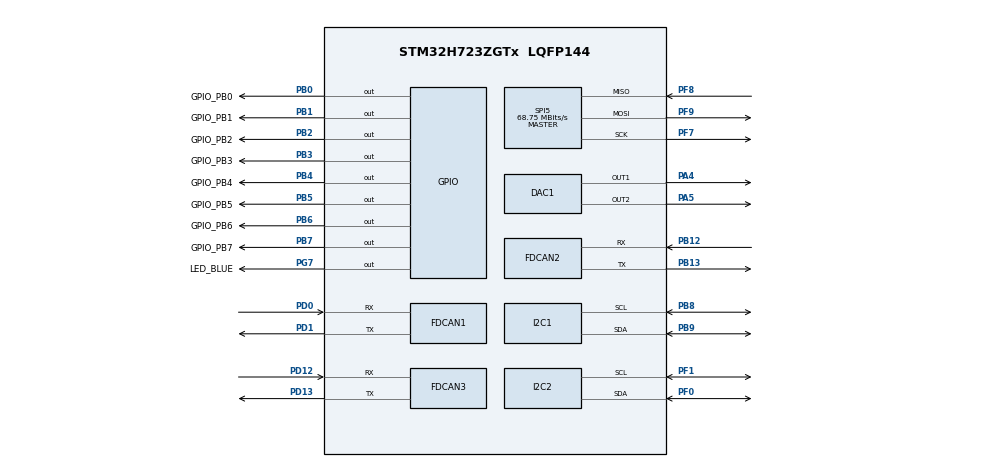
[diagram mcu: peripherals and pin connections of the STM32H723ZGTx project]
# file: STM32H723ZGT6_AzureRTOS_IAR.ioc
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CORTEX_M7.default_mode_Activation=1
DAC1.DAC_Channel-DAC_OUT1=DAC_CHANNEL_1
DAC1.DAC_Channel-DAC_OUT2=DAC_CHANNEL_2
FDCAN1.CalculateBaudRateNominal=500000
FDCAN1.CalculateTimeBitNominal=2000
FDCAN1.CalculateTimeQuantumNominal=125.0
FDCAN1.NominalPrescaler=10
FDCAN1.NominalTimeSeg1=13
FDCAN1.NominalTimeSeg2=2
FDCAN1.TxBuffersNbr=32
FDCAN2.CalculateBaudRateNominal=500000
FDCAN2.CalculateTimeBitNominal=2000
FDCAN2.CalculateTimeQuantumNominal=125.0
FDCAN2.NominalPrescaler=10
FDCAN2.NominalTimeSeg1=13
FDCAN2.NominalTimeSeg2=2
FDCAN2.TxBuffersNbr=32
FDCAN3.CalculateBaudRateNominal=500000
FDCAN3.CalculateTimeBitNominal=2000
FDCAN3.CalculateTimeQuantumNominal=125.0
FDCAN3.NominalPrescaler=10
FDCAN3.NominalTimeSeg1=13
FDCAN3.NominalTimeSeg2=2
FDCAN3.TxBuffersNbr=32
I2C1.Timing=0x60404E72
I2C2.Timing=0x60404E72
Mcu.Family=STM32H7
Mcu.Name=STM32H723ZGTx
Mcu.Package=LQFP144
NVIC.PriorityGroup=NVIC_PRIORITYGROUP_4
NVIC.TIM23_IRQn=true\:15\:0\:false\:false\:true\:false\:false\:true\:true
NVIC.TimeBase=TIM23_IRQn
NVIC.TimeBaseIP=TIM23
PA4.Signal=COMP_DAC11_group
PA5.Signal=COMP_DAC12_group
PB0.GPIO_Label=GPIO_PB0
PB0.Signal=GPIO_Output
PB1.GPIO_Label=GPIO_PB1
PB1.Signal=GPIO_Output
PB12.Mode=FDCAN_Activate
PB12.Signal=FDCAN2_RX
PB13.Mode=FDCAN_Activate
PB13.Signal=FDCAN2_TX
PB2.GPIO_Label=GPIO_PB2
PB2.Signal=GPIO_Output
PB3(JTDO/TRACESWO).GPIO_Label=GPIO_PB3
PB3(JTDO/TRACESWO).Signal=GPIO_Output
PB4(NJTRST).GPIO_Label=GPIO_PB4
PB4(NJTRST).Signal=GPIO_Output
PB5.GPIO_Label=GPIO_PB5
PB5.Signal=GPIO_Output
PB6.GPIO_Label=GPIO_PB6
PB6.Signal=GPIO_Output
PB7.GPIO_Label=GPIO_PB7
PB7.Signal=GPIO_Output
PB8.Mode=I2C
PB8.Signal=I2C1_SCL
PB9.Mode=I2C
PB9.Signal=I2C1_SDA
PD0.Mode=FDCAN_Activate
PD0.Signal=FDCAN1_RX
PD1.Mode=FDCAN_Activate
PD1.Signal=FDCAN1_TX
PD12.Mode=FDCAN_Activate
PD12.Signal=FDCAN3_RX
PD13.Mode=FDCAN_Activate
PD13.Signal=FDCAN3_TX
PF0.Mode=I2C
PF0.Signal=I2C2_SDA
PF1.Mode=I2C
PF1.Signal=I2C2_SCL
PF7.Mode=Full_Duplex_Master
PF7.Signal=SPI5_SCK
PF8.Mode=Full_Duplex_Master
PF8.Signal=SPI5_MISO
PF9.Mode=Full_Duplex_Master
PF9.Signal=SPI5_MOSI
PG7.GPIO_Label=LED_BLUE
PG7.Signal=GPIO_Output
PH0-OSC_IN.Mode=HSE-External-Oscillator
PH0-OSC_IN.Signal=RCC_OSC_IN
PH1-OSC_OUT.Mode=HSE-External-Oscillator
PH1-OSC_OUT.Signal=RCC_OSC_OUT
ProjectManager.HeapSize=0x200
ProjectManager.StackSize=0x400
ProjectManager.TargetToolchain=EWARM V8.50
RCC.ADCFreq_Value=80000000
RCC.APB1Freq_Value=137500000
RCC.APB2Freq_Value=137500000
RCC.APB3Freq_Value=137500000
RCC.APB4Freq_Value=137500000
RCC.CortexFreq_Value=550000000
RCC.D1PPRE=RCC_APB3_DIV2
RCC.D2PPRE1=RCC_APB1_DIV2
RCC.D2PPRE2=RCC_APB2_DIV2
RCC.D3PPRE=RCC_APB4_DIV2
RCC.DIVM1=2
RCC.DIVM2=25
RCC.DIVN1=44
RCC.DIVN2=160
RCC.DIVP1=1
RCC.FDCANCLockSelection=RCC_FDCANCLKSOURCE_PLL2
RCC.HCLKFreq_Value=275000000
RCC.HPRE=RCC_HCLK_DIV2
RCC.PLL2FRACN=0
RCC.PLL3FRACN=0
RCC.PLLFRACN=0
RCC.PLLSourceVirtual=RCC_PLLSOURCE_HSE
RCC.SYSCLKFreq_VALUE=550000000
RCC.SYSCLKSource=RCC_SYSCLKSOURCE_PLLCLK
RCC.USBFreq_Value=275000000
SH.COMP_DAC11_group.0=DAC1_OUT1,DAC_OUT1
SH.COMP_DAC12_group.0=DAC1_OUT2,DAC_OUT2
SPI5.CalculateBaudRate=68.75 MBits/s
SPI5.Direction=SPI_DIRECTION_2LINES
SPI5.Mode=SPI_MODE_MASTER
SPI5.VirtualType=VM_MASTER
STMicroelectronics.X-CUBE-AZRTOS-H7.3.4.0.TX_APP_CREATION=1
STMicroelectronics.X-CUBE-AZRTOS-H7.3.4.0.TX_APP_GENERATE_INIT_CODE=true
STMicroelectronics.X-CUBE-AZRTOS-H7.3.4.0.TX_APP_MEM_POOL_SIZE=8192
STMicroelectronics.X-CUBE-AZRTOS-H7.3.4.0.TX_APP_MSG_QUEUE_CREATION=0
STMicroelectronics.X-CUBE-AZRTOS-H7.3.4.0.TX_APP_MUTEX_CREATION=0
STMicroelectronics.X-CUBE-AZRTOS-H7.3.4.0.TX_APP_SEM_CREATION=0
STMicroelectronics.X-CUBE-AZRTOS-H7.3.4.0.TX_TIMER_TICKS_PER_SECOND=1000
STMicroelectronics.X-CUBE-AZRTOS-H7.3.4.0.ThreadXCcRTOSJjThreadXJjCore=true
STMicroelectronics.X-CUBE-AZRTOS-H7.3.4.0_IsAnAzureRtosMw=true
VP_MEMORYMAP_VS_MEMORYMAP.Mode=CurAppReg
VP_STMicroelectronics.X-CUBE-AZRTOS-H7_VS_RTOSJjThreadX_6.4.0_3.4.0.Mode=RTOSJjThreadX
VP_SYS_VS_tim23.Mode=TIM23
board=custom

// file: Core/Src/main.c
/* USER CODE BEGIN Header */
/**
  ******************************************************************************
  * @file           : main.c
  * @brief          : Main program body
  ******************************************************************************
  * @attention
  *
  * Copyright (c) 2026 STMicroelectronics.
  * All rights reserved.
  *
  * This software is licensed under terms that can be found in the LICENSE file
  * in the root directory of this software component.
  * If no LICENSE file comes with this software, it is provided AS-IS.
  *
  ******************************************************************************
  */
/* USER CODE END Header */
#include "app_threadx.h"
#include "main.h"

DAC_HandleTypeDef hdac1;

FDCAN_HandleTypeDef hfdcan1;
FDCAN_HandleTypeDef hfdcan2;
FDCAN_HandleTypeDef hfdcan3;

I2C_HandleTypeDef hi2c1;
I2C_HandleTypeDef hi2c2;

SPI_HandleTypeDef hspi5;

void SystemClock_Config(void);
void PeriphCommonClock_Config(void);
static void MPU_Config(void);
static void MX_GPIO_Init(void);
static void MX_FDCAN1_Init(void);
static void MX_FDCAN2_Init(void);
static void MX_FDCAN3_Init(void);
static void MX_DAC1_Init(void);
static void MX_SPI5_Init(void);
static void MX_I2C1_Init(void);
static void MX_I2C2_Init(void);

int main(void)
{

  /* MPU Configuration--------------------------------------------------------*/
  MPU_Config();

  /* MCU Configuration--------------------------------------------------------*/

  /* Reset of all peripherals, Initializes the Flash interface and the Systick. */
  HAL_Init();

  /* Configure the system clock */
  SystemClock_Config();

  /* Configure the peripherals common clocks */
  PeriphCommonClock_Config();

  /* Initialize all configured peripherals */
  MX_GPIO_Init();
  MX_FDCAN1_Init();
  MX_FDCAN2_Init();
  MX_FDCAN3_Init();
  MX_DAC1_Init();
  MX_SPI5_Init();
  MX_I2C1_Init();
  MX_I2C2_Init();

  MX_ThreadX_Init();

  /* We should never get here as control is now taken by the scheduler */

  /* Infinite loop */
  while (1)
  {

    /* USER CODE BEGIN 3 */
    //HAL_GPIO_TogglePin(GPIOG, GPIO_PIN_7);
  }
  /* USER CODE END 3 */
}

void SystemClock_Config(void)
{
  RCC_OscInitTypeDef RCC_OscInitStruct = {0};
  RCC_ClkInitTypeDef RCC_ClkInitStruct = {0};

  /** Supply configuration update enable
  */
  HAL_PWREx_ConfigSupply(PWR_LDO_SUPPLY);

  /** Configure the main internal regulator output voltage
  */
  __HAL_PWR_VOLTAGESCALING_CONFIG(PWR_REGULATOR_VOLTAGE_SCALE0);

  while(!__HAL_PWR_GET_FLAG(PWR_FLAG_VOSRDY)) {}

  /** Initializes the RCC Oscillators according to the specified parameters
  * in the RCC_OscInitTypeDef structure.
  */
  RCC_OscInitStruct.OscillatorType = RCC_OSCILLATORTYPE_HSE;
  RCC_OscInitStruct.HSEState = RCC_HSE_ON;
  RCC_OscInitStruct.PLL.PLLState = RCC_PLL_ON;
  RCC_OscInitStruct.PLL.PLLSource = RCC_PLLSOURCE_HSE;
  RCC_OscInitStruct.PLL.PLLM = 2;
  RCC_OscInitStruct.PLL.PLLN = 44;
  RCC_OscInitStruct.PLL.PLLP = 1;
  RCC_OscInitStruct.PLL.PLLQ = 2;
  RCC_OscInitStruct.PLL.PLLR = 2;
  RCC_OscInitStruct.PLL.PLLRGE = RCC_PLL1VCIRANGE_3;
  RCC_OscInitStruct.PLL.PLLVCOSEL = RCC_PLL1VCOWIDE;
  RCC_OscInitStruct.PLL.PLLFRACN = 0;
  if (HAL_RCC_OscConfig(&RCC_OscInitStruct) != HAL_OK)
  {
    Error_Handler();
  }

  /** Initializes the CPU, AHB and APB buses clocks
  */
  RCC_ClkInitStruct.ClockType = RCC_CLOCKTYPE_HCLK|RCC_CLOCKTYPE_SYSCLK
                              |RCC_CLOCKTYPE_PCLK1|RCC_CLOCKTYPE_PCLK2
                              |RCC_CLOCKTYPE_D3PCLK1|RCC_CLOCKTYPE_D1PCLK1;
  RCC_ClkInitStruct.SYSCLKSource = RCC_SYSCLKSOURCE_PLLCLK;
  RCC_ClkInitStruct.SYSCLKDivider = RCC_SYSCLK_DIV1;
  RCC_ClkInitStruct.AHBCLKDivider = RCC_HCLK_DIV2;
  RCC_ClkInitStruct.APB3CLKDivider = RCC_APB3_DIV2;
  RCC_ClkInitStruct.APB1CLKDivider = RCC_APB1_DIV2;
  RCC_ClkInitStruct.APB2CLKDivider = RCC_APB2_DIV2;
  RCC_ClkInitStruct.APB4CLKDivider = RCC_APB4_DIV2;

  if (HAL_RCC_ClockConfig(&RCC_ClkInitStruct, FLASH_LATENCY_3) != HAL_OK)
  {
    Error_Handler();
  }
}

void PeriphCommonClock_Config(void)
{
  RCC_PeriphCLKInitTypeDef PeriphClkInitStruct = {0};

  /** Initializes the peripherals clock
  */
  PeriphClkInitStruct.PeriphClockSelection = RCC_PERIPHCLK_FDCAN;
  PeriphClkInitStruct.PLL2.PLL2M = 25;
  PeriphClkInitStruct.PLL2.PLL2N = 160;
  PeriphClkInitStruct.PLL2.PLL2P = 2;
  PeriphClkInitStruct.PLL2.PLL2Q = 2;
  PeriphClkInitStruct.PLL2.PLL2R = 2;
  PeriphClkInitStruct.PLL2.PLL2RGE = RCC_PLL2VCIRANGE_0;
  PeriphClkInitStruct.PLL2.PLL2VCOSEL = RCC_PLL2VCOMEDIUM;
  PeriphClkInitStruct.PLL2.PLL2FRACN = 0;
  PeriphClkInitStruct.FdcanClockSelection = RCC_FDCANCLKSOURCE_PLL2;
  if (HAL_RCCEx_PeriphCLKConfig(&PeriphClkInitStruct) != HAL_OK)
  {
    Error_Handler();
  }
}

static void MX_DAC1_Init(void)
{

  DAC_ChannelConfTypeDef sConfig = {0};

  /** DAC Initialization
  */
  hdac1.Instance = DAC1;
  if (HAL_DAC_Init(&hdac1) != HAL_OK)
  {
    Error_Handler();
  }

  /** DAC channel OUT1 config
  */
  sConfig.DAC_SampleAndHold = DAC_SAMPLEANDHOLD_DISABLE;
  sConfig.DAC_Trigger = DAC_TRIGGER_NONE;
  sConfig.DAC_OutputBuffer = DAC_OUTPUTBUFFER_ENABLE;
  sConfig.DAC_ConnectOnChipPeripheral = DAC_CHIPCONNECT_DISABLE;
  sConfig.DAC_UserTrimming = DAC_TRIMMING_FACTORY;
  if (HAL_DAC_ConfigChannel(&hdac1, &sConfig, DAC_CHANNEL_1) != HAL_OK)
  {
    Error_Handler();
  }

  /** DAC channel OUT2 config
  */
  if (HAL_DAC_ConfigChannel(&hdac1, &sConfig, DAC_CHANNEL_2) != HAL_OK)
  {
    Error_Handler();
  }

}

static void MX_FDCAN1_Init(void)
{

  hfdcan1.Instance = FDCAN1;
  hfdcan1.Init.FrameFormat = FDCAN_FRAME_CLASSIC;
  hfdcan1.Init.Mode = FDCAN_MODE_NORMAL;
  hfdcan1.Init.AutoRetransmission = DISABLE;
  hfdcan1.Init.TransmitPause = DISABLE;
  hfdcan1.Init.ProtocolException = DISABLE;
  hfdcan1.Init.NominalPrescaler = 10;
  hfdcan1.Init.NominalSyncJumpWidth = 1;
  hfdcan1.Init.NominalTimeSeg1 = 13;
  hfdcan1.Init.NominalTimeSeg2 = 2;
  hfdcan1.Init.DataPrescaler = 1;
  hfdcan1.Init.DataSyncJumpWidth = 1;
  hfdcan1.Init.DataTimeSeg1 = 1;
  hfdcan1.Init.DataTimeSeg2 = 1;
  hfdcan1.Init.MessageRAMOffset = 0;
  hfdcan1.Init.StdFiltersNbr = 0;
  hfdcan1.Init.ExtFiltersNbr = 0;
  hfdcan1.Init.RxFifo0ElmtsNbr = 0;
  hfdcan1.Init.RxFifo0ElmtSize = FDCAN_DATA_BYTES_8;
  hfdcan1.Init.RxFifo1ElmtsNbr = 0;
  hfdcan1.Init.RxFifo1ElmtSize = FDCAN_DATA_BYTES_8;
  hfdcan1.Init.RxBuffersNbr = 0;
  hfdcan1.Init.RxBufferSize = FDCAN_DATA_BYTES_8;
  hfdcan1.Init.TxEventsNbr = 0;
  hfdcan1.Init.TxBuffersNbr = 32;
  hfdcan1.Init.TxFifoQueueElmtsNbr = 0;
  hfdcan1.Init.TxFifoQueueMode = FDCAN_TX_FIFO_OPERATION;
  hfdcan1.Init.TxElmtSize = FDCAN_DATA_BYTES_8;
  if (HAL_FDCAN_Init(&hfdcan1) != HAL_OK)
  {
    Error_Handler();
  }

}

static void MX_FDCAN2_Init(void)
{

  hfdcan2.Instance = FDCAN2;
  hfdcan2.Init.FrameFormat = FDCAN_FRAME_CLASSIC;
  hfdcan2.Init.Mode = FDCAN_MODE_NORMAL;
  hfdcan2.Init.AutoRetransmission = DISABLE;
  hfdcan2.Init.TransmitPause = DISABLE;
  hfdcan2.Init.ProtocolException = DISABLE;
  hfdcan2.Init.NominalPrescaler = 10;
  hfdcan2.Init.NominalSyncJumpWidth = 1;
  hfdcan2.Init.NominalTimeSeg1 = 13;
  hfdcan2.Init.NominalTimeSeg2 = 2;
  hfdcan2.Init.DataPrescaler = 1;
  hfdcan2.Init.DataSyncJumpWidth = 1;
  hfdcan2.Init.DataTimeSeg1 = 1;
  hfdcan2.Init.DataTimeSeg2 = 1;
  hfdcan2.Init.MessageRAMOffset = 0;
  hfdcan2.Init.StdFiltersNbr = 0;
  hfdcan2.Init.ExtFiltersNbr = 0;
  hfdcan2.Init.RxFifo0ElmtsNbr = 0;
  hfdcan2.Init.RxFifo0ElmtSize = FDCAN_DATA_BYTES_8;
  hfdcan2.Init.RxFifo1ElmtsNbr = 0;
  hfdcan2.Init.RxFifo1ElmtSize = FDCAN_DATA_BYTES_8;
  hfdcan2.Init.RxBuffersNbr = 0;
  hfdcan2.Init.RxBufferSize = FDCAN_DATA_BYTES_8;
  hfdcan2.Init.TxEventsNbr = 0;
  hfdcan2.Init.TxBuffersNbr = 32;
  hfdcan2.Init.TxFifoQueueElmtsNbr = 0;
  hfdcan2.Init.TxFifoQueueMode = FDCAN_TX_FIFO_OPERATION;
  hfdcan2.Init.TxElmtSize = FDCAN_DATA_BYTES_8;
  if (HAL_FDCAN_Init(&hfdcan2) != HAL_OK)
  {
    Error_Handler();
  }

}

static void MX_FDCAN3_Init(void)
{

  hfdcan3.Instance = FDCAN3;
  hfdcan3.Init.FrameFormat = FDCAN_FRAME_CLASSIC;
  hfdcan3.Init.Mode = FDCAN_MODE_NORMAL;
  hfdcan3.Init.AutoRetransmission = DISABLE;
  hfdcan3.Init.TransmitPause = DISABLE;
  hfdcan3.Init.ProtocolException = DISABLE;
  hfdcan3.Init.NominalPrescaler = 10;
  hfdcan3.Init.NominalSyncJumpWidth = 1;
  hfdcan3.Init.NominalTimeSeg1 = 13;
  hfdcan3.Init.NominalTimeSeg2 = 2;
  hfdcan3.Init.DataPrescaler = 1;
  hfdcan3.Init.DataSyncJumpWidth = 1;
  hfdcan3.Init.DataTimeSeg1 = 1;
  hfdcan3.Init.DataTimeSeg2 = 1;
  hfdcan3.Init.MessageRAMOffset = 0;
  hfdcan3.Init.StdFiltersNbr = 0;
  hfdcan3.Init.ExtFiltersNbr = 0;
  hfdcan3.Init.RxFifo0ElmtsNbr = 0;
  hfdcan3.Init.RxFifo0ElmtSize = FDCAN_DATA_BYTES_8;
  hfdcan3.Init.RxFifo1ElmtsNbr = 0;
  hfdcan3.Init.RxFifo1ElmtSize = FDCAN_DATA_BYTES_8;
  hfdcan3.Init.RxBuffersNbr = 0;
  hfdcan3.Init.RxBufferSize = FDCAN_DATA_BYTES_8;
  hfdcan3.Init.TxEventsNbr = 0;
  hfdcan3.Init.TxBuffersNbr = 32;
  hfdcan3.Init.TxFifoQueueElmtsNbr = 0;
  hfdcan3.Init.TxFifoQueueMode = FDCAN_TX_FIFO_OPERATION;
  hfdcan3.Init.TxElmtSize = FDCAN_DATA_BYTES_8;
  if (HAL_FDCAN_Init(&hfdcan3) != HAL_OK)
  {
    Error_Handler();
  }

}

static void MX_I2C1_Init(void)
{

  hi2c1.Instance = I2C1;
  hi2c1.Init.Timing = 0x60404E72;
  hi2c1.Init.OwnAddress1 = 0;
  hi2c1.Init.AddressingMode = I2C_ADDRESSINGMODE_7BIT;
  hi2c1.Init.DualAddressMode = I2C_DUALADDRESS_DISABLE;
  hi2c1.Init.OwnAddress2 = 0;
  hi2c1.Init.OwnAddress2Masks = I2C_OA2_NOMASK;
  hi2c1.Init.GeneralCallMode = I2C_GENERALCALL_DISABLE;
  hi2c1.Init.NoStretchMode = I2C_NOSTRETCH_DISABLE;
  if (HAL_I2C_Init(&hi2c1) != HAL_OK)
  {
    Error_Handler();
  }

  /** Configure Analogue filter
  */
  if (HAL_I2CEx_ConfigAnalogFilter(&hi2c1, I2C_ANALOGFILTER_ENABLE) != HAL_OK)
  {
    Error_Handler();
  }

  /** Configure Digital filter
  */
  if (HAL_I2CEx_ConfigDigitalFilter(&hi2c1, 0) != HAL_OK)
  {
    Error_Handler();
  }

}

static void MX_I2C2_Init(void)
{

  hi2c2.Instance = I2C2;
  hi2c2.Init.Timing = 0x60404E72;
  hi2c2.Init.OwnAddress1 = 0;
  hi2c2.Init.AddressingMode = I2C_ADDRESSINGMODE_7BIT;
  hi2c2.Init.DualAddressMode = I2C_DUALADDRESS_DISABLE;
  hi2c2.Init.OwnAddress2 = 0;
  hi2c2.Init.OwnAddress2Masks = I2C_OA2_NOMASK;
  hi2c2.Init.GeneralCallMode = I2C_GENERALCALL_DISABLE;
  hi2c2.Init.NoStretchMode = I2C_NOSTRETCH_DISABLE;
  if (HAL_I2C_Init(&hi2c2) != HAL_OK)
  {
    Error_Handler();
  }

  /** Configure Analogue filter
  */
  if (HAL_I2CEx_ConfigAnalogFilter(&hi2c2, I2C_ANALOGFILTER_ENABLE) != HAL_OK)
  {
    Error_Handler();
  }

  /** Configure Digital filter
  */
  if (HAL_I2CEx_ConfigDigitalFilter(&hi2c2, 0) != HAL_OK)
  {
    Error_Handler();
  }

}

static void MX_SPI5_Init(void)
{

  /* SPI5 parameter configuration*/
  hspi5.Instance = SPI5;
  hspi5.Init.Mode = SPI_MODE_MASTER;
  hspi5.Init.Direction = SPI_DIRECTION_2LINES;
  hspi5.Init.DataSize = SPI_DATASIZE_4BIT;
  hspi5.Init.CLKPolarity = SPI_POLARITY_LOW;
  hspi5.Init.CLKPhase = SPI_PHASE_1EDGE;
  hspi5.Init.NSS = SPI_NSS_SOFT;
  hspi5.Init.BaudRatePrescaler = SPI_BAUDRATEPRESCALER_2;
  hspi5.Init.FirstBit = SPI_FIRSTBIT_MSB;
  hspi5.Init.TIMode = SPI_TIMODE_DISABLE;
  hspi5.Init.CRCCalculation = SPI_CRCCALCULATION_DISABLE;
  hspi5.Init.CRCPolynomial = 0x0;
  hspi5.Init.NSSPMode = SPI_NSS_PULSE_ENABLE;
  hspi5.Init.NSSPolarity = SPI_NSS_POLARITY_LOW;
  hspi5.Init.FifoThreshold = SPI_FIFO_THRESHOLD_01DATA;
  hspi5.Init.TxCRCInitializationPattern = SPI_CRC_INITIALIZATION_ALL_ZERO_PATTERN;
  hspi5.Init.RxCRCInitializationPattern = SPI_CRC_INITIALIZATION_ALL_ZERO_PATTERN;
  hspi5.Init.MasterSSIdleness = SPI_MASTER_SS_IDLENESS_00CYCLE;
  hspi5.Init.MasterInterDataIdleness = SPI_MASTER_INTERDATA_IDLENESS_00CYCLE;
  hspi5.Init.MasterReceiverAutoSusp = SPI_MASTER_RX_AUTOSUSP_DISABLE;
  hspi5.Init.MasterKeepIOState = SPI_MASTER_KEEP_IO_STATE_DISABLE;
  hspi5.Init.IOSwap = SPI_IO_SWAP_DISABLE;
  if (HAL_SPI_Init(&hspi5) != HAL_OK)
  {
    Error_Handler();
  }

}

static void MX_GPIO_Init(void)
{
  GPIO_InitTypeDef GPIO_InitStruct = {0};

  /* GPIO Ports Clock Enable */
  __HAL_RCC_GPIOF_CLK_ENABLE();
  __HAL_RCC_GPIOH_CLK_ENABLE();
  __HAL_RCC_GPIOA_CLK_ENABLE();
  __HAL_RCC_GPIOB_CLK_ENABLE();
  __HAL_RCC_GPIOD_CLK_ENABLE();
  __HAL_RCC_GPIOG_CLK_ENABLE();

  /*Configure GPIO pin Output Level */
  HAL_GPIO_WritePin(GPIOB, GPIO_PB0_Pin|GPIO_PB1_Pin|GPIO_PB2_Pin|GPIO_PB3_Pin
                          |GPIO_PB4_Pin|GPIO_PB5_Pin|GPIO_PB6_Pin|GPIO_PB7_Pin, GPIO_PIN_RESET);

  /*Configure GPIO pin Output Level */
  HAL_GPIO_WritePin(LED_BLUE_GPIO_Port, LED_BLUE_Pin, GPIO_PIN_RESET);

  /*Configure GPIO pins : GPIO_PB0_Pin GPIO_PB1_Pin GPIO_PB2_Pin GPIO_PB3_Pin
                           GPIO_PB4_Pin GPIO_PB5_Pin GPIO_PB6_Pin GPIO_PB7_Pin */
  GPIO_InitStruct.Pin = GPIO_PB0_Pin|GPIO_PB1_Pin|GPIO_PB2_Pin|GPIO_PB3_Pin
                          |GPIO_PB4_Pin|GPIO_PB5_Pin|GPIO_PB6_Pin|GPIO_PB7_Pin;
  GPIO_InitStruct.Mode = GPIO_MODE_OUTPUT_PP;
  GPIO_InitStruct.Pull = GPIO_NOPULL;
  GPIO_InitStruct.Speed = GPIO_SPEED_FREQ_LOW;
  HAL_GPIO_Init(GPIOB, &GPIO_InitStruct);

  /*Configure GPIO pin : LED_BLUE_Pin */
  GPIO_InitStruct.Pin = LED_BLUE_Pin;
  GPIO_InitStruct.Mode = GPIO_MODE_OUTPUT_PP;
  GPIO_InitStruct.Pull = GPIO_NOPULL;
  GPIO_InitStruct.Speed = GPIO_SPEED_FREQ_LOW;
  HAL_GPIO_Init(LED_BLUE_GPIO_Port, &GPIO_InitStruct);

}

 /* MPU Configuration */

void MPU_Config(void)
{
  MPU_Region_InitTypeDef MPU_InitStruct = {0};

  /* Disables the MPU */
  HAL_MPU_Disable();

  /** Initializes and configures the Region and the memory to be protected
  */
  MPU_InitStruct.Enable = MPU_REGION_ENABLE;
  MPU_InitStruct.Number = MPU_REGION_NUMBER0;
  MPU_InitStruct.BaseAddress = 0x0;
  MPU_InitStruct.Size = MPU_REGION_SIZE_4GB;
  MPU_InitStruct.SubRegionDisable = 0x87;
  MPU_InitStruct.TypeExtField = MPU_TEX_LEVEL0;
  MPU_InitStruct.AccessPermission = MPU_REGION_NO_ACCESS;
  MPU_InitStruct.DisableExec = MPU_INSTRUCTION_ACCESS_DISABLE;
  MPU_InitStruct.IsShareable = MPU_ACCESS_SHAREABLE;
  MPU_InitStruct.IsCacheable = MPU_ACCESS_NOT_CACHEABLE;
  MPU_InitStruct.IsBufferable = MPU_ACCESS_NOT_BUFFERABLE;

  HAL_MPU_ConfigRegion(&MPU_InitStruct);
  /* Enables the MPU */
  HAL_MPU_Enable(MPU_PRIVILEGED_DEFAULT);

}

void HAL_TIM_PeriodElapsedCallback(TIM_HandleTypeDef *htim)
{
  if (htim->Instance == TIM23)
  {
    HAL_IncTick();
  }
}

void Error_Handler(void)
{
  __disable_irq();
  while (1)
  {
  }
}
